# nrf9120_mlm1_modem register map
Vendor: Nordic Semiconductor; Series: nrf91; File version: 1
CPU: CM4 r0p1, little endian, MPU, no FPU, 3 interrupt priority bits
Registers are 32-bit, read-write, reset 0x0 unless marked. A register's access mark holds for its fields unless they carry their own. Offsets are from the block's base; [hi:lo] are bit positions; lines under a group give offsets from that group; {n}, {i} and the like mark numbered series; 'fields as' and 'values as' point back to an identical list.

## DPOWER — Power Control
Base 0x40015000; alternate view of DCLOCK
0x78 TASKS_CONSTLAT wo — Enable constant latency mode. When going to sleep: CPU is clock gated, but regulators, oscillators and clock tree is kept on.
  [0] TASKS_CONSTLAT
    1=Trigger task
0x7C TASKS_LOWPWR wo — Enable low power mode (variable latency) When going to sleep: Oscillators are switched off (if nothing else is requesting clocks). Regulators are switched off (if nothing else is requesting power).
  [0] TASKS_LOWPWR
    1=Trigger task
0x108 EVENTS_POFWARN — Power failure warning
  [0] EVENTS_POFWARN
    0=NotGenerated (Event not generated); 1=Generated (Event generated)
0x114 EVENTS_SLEEPENTER — CPU entered WFI/WFE sleep
  [0] EVENTS_SLEEPENTER
    values as EVENTS_POFWARN.EVENTS_POFWARN
0x118 EVENTS_SLEEPEXIT — CPU exited WFI/WFE sleep
  [0] EVENTS_SLEEPEXIT
    values as EVENTS_POFWARN.EVENTS_POFWARN
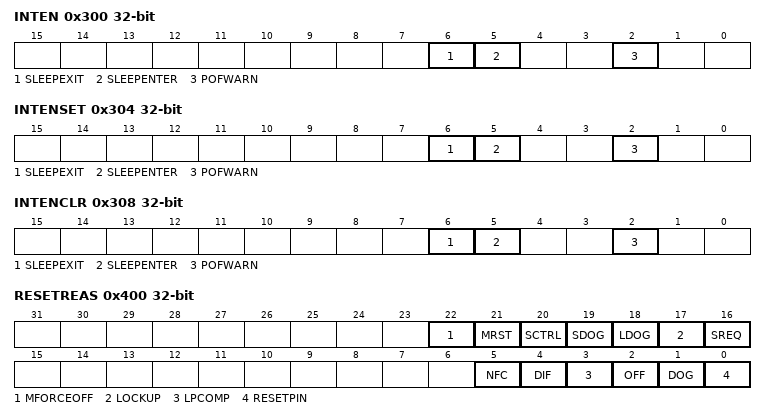
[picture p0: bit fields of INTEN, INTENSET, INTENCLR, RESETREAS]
0x300 INTEN — Enable or disable interrupt
  [all] fields
    0=Disabled; 1=Enabled
  [6] SLEEPEXIT — Enable or disable interrupt for event SLEEPEXIT
  [5] SLEEPENTER — Enable or disable interrupt for event SLEEPENTER
  [2] POFWARN — Enable or disable interrupt for event POFWARN
0x304 INTENSET — Enable interrupt
  [all] fields
    on read: 0=Disabled (Read: Disabled); 1=Enabled (Read: Enabled) | on write: 1=Set (Enable)
  [6] SLEEPEXIT — Write '1' to enable interrupt for event SLEEPEXIT
  [5] SLEEPENTER — Write '1' to enable interrupt for event SLEEPENTER
  [2] POFWARN — Write '1' to enable interrupt for event POFWARN
0x308 INTENCLR — Disable interrupt
  [all] fields
    on read: 0=Disabled (Read: Disabled); 1=Enabled (Read: Enabled) | on write: 1=Clear (Disable)
  [6] SLEEPEXIT — Write '1' to disable interrupt for event SLEEPEXIT
  [5] SLEEPENTER — Write '1' to disable interrupt for event SLEEPENTER
  [2] POFWARN — Write '1' to disable interrupt for event POFWARN
0x400 RESETREAS — Reset reason
  [all] fields
    0=NotDetected; 1=Detected
  [22] MFORCEOFF — Force off reset from MCUMASTER detected
  [21] MRST — CPU reset from MCUMASTER detected
  [20] SCTRL — Reset from secure control detected
  [19] SDOG — Reset from secure watchdog detected
  [18] LDOG — Reset from local watchdog detected
  [17] LOCKUP — Reset from CPU lock-up detected
  [16] SREQ — Reset from AIRCR.SYSRESETREQ detected
  [5] NFC — Reset due to wake up from System OFF mode by NFC field detect
  [4] DIF — Reset due to wake up from System OFF mode when wakeup is triggered from entering into debug interface mode
  [3] LPCOMP — Reset due to wake up from System OFF mode when wakeup is triggered from ANADETECT signal from LPCOMP
  [2] OFF — Reset due to wake up from System OFF mode when wakeup is triggered from DETECT signal from GPIO
  [1] DOG — Reset from global watchdog detected
  [0] RESETPIN — Reset from pin-reset detected
0x510 SLEEPCNF — Sleep configuration
  [0] SLEEPMODE
    0=LIGHTSLEEP (Light sleep FF retention mode will be used if available. Otherwise FFs are kept powered.); 1=DEEPSLEEP (Deep sleep (wake from reset) No FF retention (needs wake from reset).)
{0x51C+4i} GPREGRET[{i}] (i=0..1) — Description collection: General purpose retention register
  [7:0] GPREGRET — General purpose retention register
0x610 DSP group — Control register for DSP
  0x00 RESET reset 0x1 — Reset DSP subsystem
    [0] RESET
      0=Release CPU reset signal; 1=Hold CPU reset signal
  0x04 FORCEOFF reset 0x1 — Force off power and clock in DSP subsystem
    [0] FORCEOFF — RESET
      0=Release force off signal; 1=Hold force off signal
  0x08 FORCEON — Force on power and clock in DSP subsystem
    [0] FORCEON — Forces on power and clock in DSP subsystem
      0=Release force on signal; 1=Hold force on signal
  0x0C HALT reset 0x1 — Halt DSP subsystem
    [0] HALT
      0=Release halt signal; 1=Hold halt signal
0x620 LYNX group — Control register for Lynx RF subsystem
  0x00 RESET reset 0x1 — Reset Lynx RF subsystem
    [0] RESET — CPU soft reset
      0=Release CPU reset signal; 1=Hold CPU reset signal
  0x04 FORCEOFF reset 0x1 — Force off power and clock in Lynx RF subsystem
    fields as DSP.FORCEOFF
  0x08 FORCEON — Force on Lynx RF subsystem
    [0] FORCEON — Forces an power and clock DSP subsystem
      0=Release force on signal; 1=Hold force on signal
